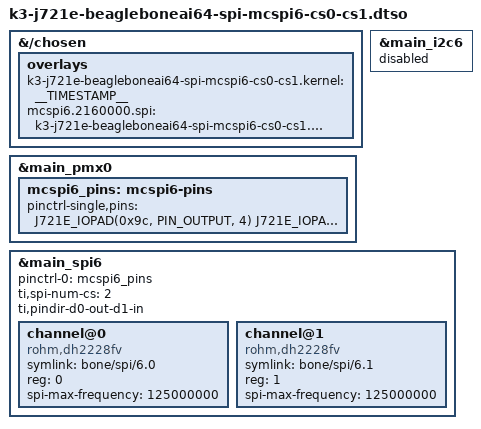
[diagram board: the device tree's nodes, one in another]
// SPDX-License-Identifier: GPL-2.0-only OR MIT
/*
 * DT Overlay for SPI6 CS0 and CS1 on the BeagleBoneAI64.
 * Pins:
 * - CS0: P9_17a (SPI6_CS0)
 * - CS1: P9_23 (SPI6_CS1)
 * - CLK: P9_22a (SPI6_CLK)
 * - MOSI: P9_21a (SPI6_D0)
 * - MISO: P9_18a (SPI6_D1)
 *
 * Copyright (C) 2023 Texas Instruments Incorporated - https://www.ti.com/
 */

/* 
 *WARNING!!!
 * This overlay will not mux if there are pin conflicts. For example, by default i2c6 is enabled taking
 * pins P9_17 and P9_18. To stop pin conflicts this overlay disables i2c6.
 *
 * Look for errors in `sudo beagle-version \| grep UBOOT`
 */

/dts-v1/;
/plugin/;

#include <dt-bindings/gpio/gpio.h>
#include "ti/k3-pinctrl.h"

/*
 * Helper to show loaded overlays under: /proc/device-tree/chosen/overlays/
*/
&{/chosen} {
    overlays {
        k3-j721e-beagleboneai64-spi-mcspi6-cs0-cs1.kernel = __TIMESTAMP__;
        mcspi6.2160000.spi = "k3-j721e-beagleboneai64-spi-mcspi6-cs0-cs1.2160000";
    };
};

/* Disable i2c6 to free up pins p9_17 and p9_18 */
&main_i2c6 {
        status = "disable";
};

/* To figure out which SoC pad numbers go with which BB header pins, look at columns A and B
 * in the following spreadsheet. To figure out mux modes, look at row 10.
 * https://drive.google.com/file/d/15NLaUeMBy-iT8s6rFrP4Esf0Qh57T4xu/view?pli=1
 *
 * To figure out the addresses of SoC pads, look at table "Table 5-125. Pin Multiplexing" in the TDA4VM Processors datasheet
 * https://www.ti.com/lit/ds/symlink/tda4vm.pdf?ts=1741890214437&ref_url=https%253A%252F%252Fwww.ti.com%252Fproduct%252FTDA4VM
 *
 *
 * ~~ Walkthrough of process to figure out muxing ~~
 *
 * From the spreadsheet we see that pad AC22 is the first pad on BB header pin P9_22. AC22 is thus known as P9_22a. The alternative
 * pad, U29, is known as P9_22b. From Looking at the TDA4VM datasheet, we see that AC22(aka P9_22a) has the address 0x00011C09C. For 
 * the J721E_IOPAD() pin-mux macro, we need the bottom 24bits of the address, so 0x09c, or 0x9c. 
 * 
 * To mux AC22(aka P9_22a) to be SPI6_CLK, as figured out from the spreadsheet, we need to set AC22 to mux-mode 4. And since
 * a SPI clock is an output signal, the pin should be put set to PIN_OUTPUT mode.
 * So `J721E_IOPAD(0x9c, PIN_OUTPUT, 4)`
 * 
 * We will also need to disable the second SoC pad that shares the same BB header pin. The SoC pad known as pin P9_22b, or 
 * pad U29. Using the same process as walked through with pad AC22, you get the following:
 * `J721E_IOPAD(0x170, PIN_DISABLE, 7)`
 *
 * So to mux SPI6_CLK on BB pin P9_22:
 * J721E_IOPAD(0x9c, PIN_OUTPUT, 4)
 * J721E_IOPAD(0x170, PIN_DISABLE, 7)
 *
*/
&main_pmx0 {
	mcspi6_pins: mcspi6-pins {
		pinctrl-single,pins = <            
            /* Used TI SysConfig app to generate these, had manually adjust output modes */
            J721E_IOPAD(0x9c, PIN_OUTPUT, 4) /* (AC22) PRG1_PRU1_GPO17.SPI6_CLK P9_22a */
			J721E_IOPAD(0x74, PIN_OUTPUT, 4) /* (AC21) PRG1_PRU1_GPO7.SPI6_CS0 P9_17a */
			J721E_IOPAD(0xa0, PIN_OUTPUT, 4) /* (AJ22) PRG1_PRU1_GPO18.SPI6_D0 MOSI P9_21a */
			J721E_IOPAD(0xa4, PIN_INPUT, 4) /* (AH22) PRG1_PRU1_GPO19.SPI6_D1 MISO P9_18a */
            J721E_IOPAD(0x28, PIN_OUTPUT, 4) /* (AG20) PRG1_PRU1_GPO8.SPI6_CS1 P9_23 */

            /* Disable SoC pins that share same BB header pins */
            /* These pins conflict */
            J721E_IOPAD(0x170, PIN_DISABLE, 7) /* (U29) disable P9_22b */
            J721E_IOPAD(0x1D0, PIN_DISABLE, 7) /* (AA3) disable P9_17b */
            J721E_IOPAD(0x16C, PIN_DISABLE, 7) /* (U28) disable P9_21b */
            J721E_IOPAD(0x1E4, PIN_DISABLE, 7) /* (Y2) disable P9_18b */
            /* No conflicting pad for P9_23 (AG20), so no disable needed */
		>;
	};
};

/*
 * SPI6 controller configuration with support for two chip selects (CS0 and CS1).
 */
&main_spi6 {
    #address-cells = <1>;
    #size-cells = <0>;
    pinctrl-names = "default";
    pinctrl-0 = <&mcspi6_pins>;
    ti,spi-num-cs = <2>; /* Support two chip selects */
    ti,pindir-d0-out-d1-in;
    status = "okay";

	/* THIS IS FOR SPIDEV, to see device at /dev/bone/spi, first run `sudo modprobe spidev` */
	/* When controlling SPI from outside linux, you may want to delete this spidev stuff */

    /* Channel for SPI6_CS0 */
    channel@0 {
        symlink = "bone/spi/6.0";
        compatible = "rohm,dh2228fv";
        reg = <0>; /* CE0 */
        spi-max-frequency = <125000000>;
    };

    /* Channel for SPI6_CS1 */
    channel@1 {
        symlink = "bone/spi/6.1";
        compatible = "rohm,dh2228fv";
        reg = <1>;  /* CE1 */
        spi-max-frequency = <125000000>;
    };
    
};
